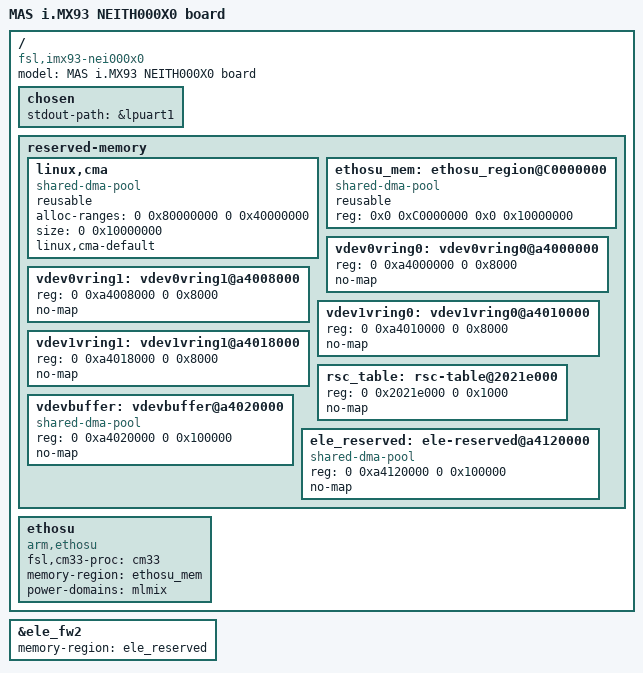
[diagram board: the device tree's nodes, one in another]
// SPDX-License-Identifier: (GPL-2.0+ OR MIT)
/*
 * Copyright 2022 NXP
 */

/dts-v1/;

#include "imx93.dtsi"
#include "imx93-nei000x0-osm.dtsi"
#include "imx93-nei000x0-adapter.dtsi"
#include "imx93-nei000x0-carrier.dtsi"
#include "imx93-nei000x0-lvds-panel.dtsi"
#include "imx93-nei000x0-gpio-labels.dtsi"

&ele_fw2 {
	memory-region = <&ele_reserved>;
};

/ {
	model = "MAS i.MX93 NEITH000X0 board";
	compatible = "fsl,imx93-nei000x0", "fsl,imx93";

	chosen {
		stdout-path = &lpuart1;
	};

	reserved-memory {
		#address-cells = <2>;
		#size-cells = <2>;
		ranges;

		linux,cma {
			compatible = "shared-dma-pool";
			reusable;
			alloc-ranges = <0 0x80000000 0 0x40000000>;
			size = <0 0x10000000>;
			linux,cma-default;
		};

		ethosu_mem: ethosu_region@C0000000 {
			compatible = "shared-dma-pool";
			reusable;
			reg = <0x0 0xC0000000 0x0 0x10000000>;
		};

		vdev0vring0: vdev0vring0@a4000000 {
			reg = <0 0xa4000000 0 0x8000>;
			no-map;
		};

		vdev0vring1: vdev0vring1@a4008000 {
			reg = <0 0xa4008000 0 0x8000>;
			no-map;
		};

		vdev1vring0: vdev1vring0@a4010000 {
			reg = <0 0xa4010000 0 0x8000>;
			no-map;
		};

		vdev1vring1: vdev1vring1@a4018000 {
			reg = <0 0xa4018000 0 0x8000>;
			no-map;
		};

		rsc_table: rsc-table@2021e000 {
			reg = <0 0x2021e000 0 0x1000>;
			no-map;
		};

		vdevbuffer: vdevbuffer@a4020000 {
			compatible = "shared-dma-pool";
			reg = <0 0xa4020000 0 0x100000>;
			no-map;
		};

		ele_reserved: ele-reserved@a4120000 {
			compatible = "shared-dma-pool";
			reg = <0 0xa4120000 0 0x100000>;
			no-map;
		};
	};

	ethosu {
		compatible = "arm,ethosu";
		fsl,cm33-proc = <&cm33>;
		memory-region = <&ethosu_mem>;
		power-domains = <&mlmix>;
	};

};

